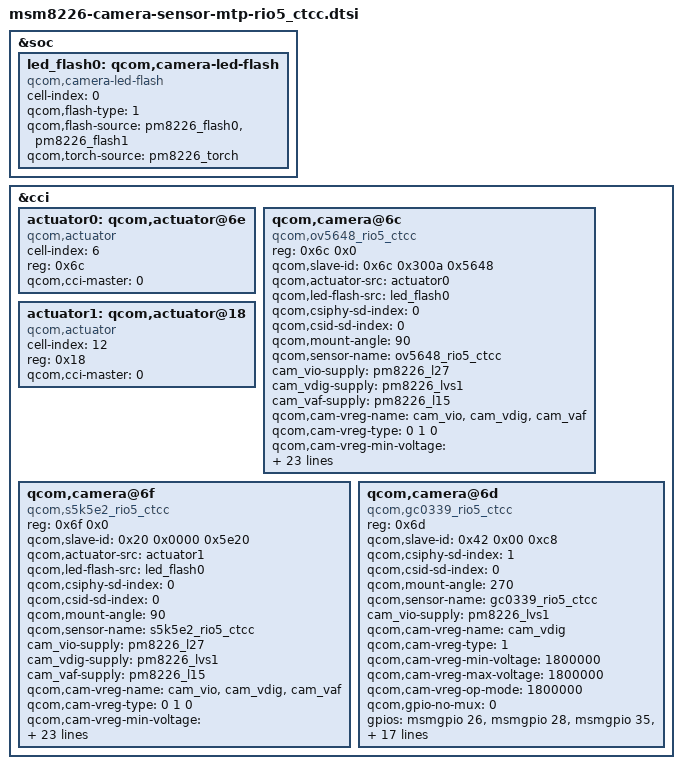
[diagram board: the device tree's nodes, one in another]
/*
 * Copyright (c) 2013, The Linux Foundation. All rights reserved.
 *
 * This program is free software; you can redistribute it and/or modify
 * it under the terms of the GNU General Public License version 2 and
 * only version 2 as published by the Free Software Foundation.
 *
 * This program is distributed in the hope that it will be useful,
 * but WITHOUT ANY WARRANTY; without even the implied warranty of
 * MERCHANTABILITY or FITNESS FOR A PARTICULAR PURPOSE.  See the
 * GNU General Public License for more details.
 *         Modify History For This Module
 * When           Who             What,Where,Why
 * --------------------------------------------------------------------------------------
 * 13/08/22      Hu Jin       Add driver for RoilTF's 1st main CAM
 * 13/08/31      Hu Jin       Add driver for RoilTF's 1st sub CAM
 * 13/12/03      Hu Jin       for rio4g's tuning process(porting from rio4g)
 * 13/12/09      Hu Jin       same with miata ov5648AF
 * 13/12/10      Wang Penglei       Add driver for RIO5 CTCC's 1st sub CAM GC0339
 * 13/12/14      Hu Jin		  same with miata-2
 * 14/01/02      Hu Jin       diff with miata 5M(mount reverse 90°)
 * 14/01/04      Hu Jin       Pictures taken are upside down
 * 14/01/19      Hu Jin       Camera can not be found on production
 * 14/01/21      Hu Jin	  Sub CAM timing
 * 14/02/14      Hu Jin			2nd camera
 * --------------------------------------------------------------------------------------
 */

&soc {

	led_flash0: qcom,camera-led-flash {
		cell-index = <0>;
		compatible = "qcom,camera-led-flash";
		qcom,flash-type = <1>;
		qcom,flash-source = <&pm8226_flash0 &pm8226_flash1>;
		qcom,torch-source = <&pm8226_torch>;
	};
};

&cci {

	actuator0: qcom,actuator@6e {
		cell-index = <6>;/* [PLATFORM]-Mod by TCTNB.HJ, 2013/12/14*/
		reg = <0x6c>;
		compatible = "qcom,actuator";
		qcom,cci-master = <0>;
	};

/*
	qcom,camera@6f {
		compatible = "qcom,ov8825";
		reg = <0x6f>;
		qcom,slave-id = <0x6c 0x300a 0x8825>;
		qcom,csiphy-sd-index = <0>;
		qcom,csid-sd-index = <0>;
		qcom,actuator-src = <&actuator0>;
		qcom,led-flash-src = <&led_flash0>;
		qcom,mount-angle = <270>;
		qcom,sensor-name = "ov8825";
		cam_vdig-supply = <&pm8226_l5>;
		cam_vana-supply = <&pm8226_l19>;
		cam_vio-supply = <&pm8226_lvs1>;
		cam_vaf-supply = <&pm8226_l15>;
		qcom,cam-vreg-name = "cam_vdig", "cam_vio", "cam_vana",
							 "cam_vaf";
		qcom,cam-vreg-type = <0 1 0 0>;
		qcom,cam-vreg-min-voltage = <1200000 0 2850000 2800000>;
		qcom,cam-vreg-max-voltage = <1200000 0 2850000 2800000>;
		qcom,cam-vreg-op-mode = <200000 0 80000 100000>;
		qcom,gpio-no-mux = <0>;
		gpios = <&msmgpio 26 0>,
			<&msmgpio 37 0>,
			<&msmgpio 35 0>;
		qcom,gpio-reset = <1>;
		qcom,gpio-standby = <2>;
		qcom,gpio-req-tbl-num = <0 1 2>;
		qcom,gpio-req-tbl-flags = <1 0 0>;
		qcom,gpio-req-tbl-label = "CAMIF_MCLK",
			"CAM_RESET1",
			"CAM_STANDBY";
		qcom,csi-lane-assign = <0x4320>;
		qcom,csi-lane-mask = <0x1f>;
		qcom,sensor-position = <0>;
		qcom,sensor-mode = <1>;
		qcom,cci-master = <0>;
	};
*/
/*
	qcom,camera@6d {
		compatible = "qcom,ov9724";
		reg = <0x6d>;
		qcom,slave-id = <0x20 0x0 0x9724>;
		qcom,csiphy-sd-index = <1>;
		qcom,csid-sd-index = <1>;
		qcom,mount-angle = <270>;
		qcom,sensor-name = "ov9724";
		cam_vdig-supply = <&pm8226_l5>;
		cam_vana-supply = <&pm8226_l19>;
		cam_vio-supply = <&pm8226_lvs1>;
		qcom,cam-vreg-name = "cam_vdig", "cam_vio", "cam_vana";
		qcom,cam-vreg-type = <0 1 0>;
		qcom,cam-vreg-min-voltage = <1200000 0 2850000>;
		qcom,cam-vreg-max-voltage = <1200000 0 2850000>;
		qcom,cam-vreg-op-mode = <200000 0 80000>;
		qcom,gpio-no-mux = <0>;
		gpios = <&msmgpio 26 0>,
				<&msmgpio 28 0>,
				<&msmgpio 36 0>;
		qcom,gpio-reset = <1>;
		qcom,gpio-standby = <2>;
		qcom,gpio-req-tbl-num = <0 1 2>;
		qcom,gpio-req-tbl-flags = <1 0 0>;
		qcom,gpio-req-tbl-label = "CAMIF_MCLK",
				"CAM_RESET",
				"CAM_STANDBY";
		qcom,gpio-set-tbl-num = <1 1>;
		qcom,gpio-set-tbl-flags = <0 2>;
		qcom,gpio-set-tbl-delay = <1000 4000>;
		qcom,csi-lane-assign = <0x4320>;
		qcom,csi-lane-mask = <0x3>;
		qcom,sensor-position = <1>;
		qcom,sensor-mode = <1>;
		qcom,cci-master = <0>;
		status = "ok";
	};
*/
/* [PLATFORM]-Mod-BEGIN by TCTNB.HJ, 2013/08/22, 1st main CAM dev*/
qcom,camera@6c {
    compatible = "qcom,ov5648_rio5_ctcc";
    reg = <0x6c 0x0>;
    qcom,slave-id = <0x6c 0x300a 0x5648>;
    qcom,actuator-src = <&actuator0>;
    qcom,led-flash-src = <&led_flash0>;
    qcom,csiphy-sd-index = <0>;
    qcom,csid-sd-index = <0>;
    qcom,mount-angle = <90>;
    qcom,sensor-name = "ov5648_rio5_ctcc";
    //cam_vio-supply = <&pm8226_lvs1>;
    cam_vio-supply = <&pm8226_l27>;
    cam_vdig-supply = <&pm8226_lvs1>;
    cam_vaf-supply = <&pm8226_l15>;
    qcom,cam-vreg-name = "cam_vio", "cam_vdig", "cam_vaf";
    qcom,cam-vreg-type = <0 1 0>;
    qcom,cam-vreg-min-voltage = <1500000 1800000 2800000>;
    qcom,cam-vreg-max-voltage = <1500000 1800000 2800000>;
    qcom,cam-vreg-op-mode = <1500000 1800000 100000>;
    qcom,gpio-no-mux = <0>;
    gpios = <&msmgpio 26 0>,
            <&msmgpio 37 0>,
            <&msmgpio 36 0>,
            <&msmgpio 31 0>,
            <&msmgpio 23 0>;
    qcom,gpio-reset = <1>;
    qcom,gpio-standby = <2>;
       qcom,gpio-vana = <3>;
       qcom,gpio-af-pwdm = <4>;
    qcom,gpio-req-tbl-num = <0 1 2 3 4>;
    qcom,gpio-req-tbl-flags = <1 0 0 0 0>;
    qcom,gpio-req-tbl-label = "CAMIF_MCLK",
            "CAM_RESET",
            "CAM_STANDBY",
            "CAM_VANA",
            "CAM_AF_PWDM";
    qcom,gpio-set-tbl-flags = <0 2>;
    qcom,gpio-set-tbl-delay = <1000 4000>;
    qcom,csi-lane-assign = <0x4320>;
    qcom,csi-lane-mask = <0x3>;
    qcom,sensor-position = <0>;
    qcom,sensor-mode = <0>;
    qcom,cci-master = <0>;
};
/* [PLATFORM]-Mod-END by TCTNB.HJ, 2013/08/22 */


/* [PLATFORM]-Mod-BEGIN by TCTNB.HJ, 2014/02/14, 2nd main CAM dev*/
actuator1: qcom,actuator@18 {
    cell-index = <12>;/* [PLATFORM]-Mod-BEGIN by TCTNB.HJ, 2013/11/19, 1st main CAM dev*/
    reg = <0x18>;
    compatible = "qcom,actuator";
    qcom,cci-master = <0>;
};
qcom,camera@6f {
    compatible = "qcom,s5k5e2_rio5_ctcc";
    reg = <0x6f 0x0>;
    qcom,slave-id = <0x20 0x0000 0x5e20>;
    qcom,actuator-src = <&actuator1>;
    qcom,led-flash-src = <&led_flash0>;
    qcom,csiphy-sd-index = <0>;
    qcom,csid-sd-index = <0>;
    qcom,mount-angle = <90>;
    qcom,sensor-name = "s5k5e2_rio5_ctcc";
    cam_vio-supply = <&pm8226_l27>;
    cam_vdig-supply = <&pm8226_lvs1>;
    cam_vaf-supply = <&pm8226_l15>;
    qcom,cam-vreg-name =  "cam_vio", "cam_vdig", "cam_vaf";
    qcom,cam-vreg-type = <0 1 0>;
    qcom,cam-vreg-min-voltage = <1200000 1800000 2800000>;
    qcom,cam-vreg-max-voltage = <1200000 1800000 2800000>;
    qcom,cam-vreg-op-mode = <1200000 1800000 100000>;
    qcom,gpio-no-mux = <0>;
    gpios = <&msmgpio 26 0>,
            <&msmgpio 37 0>,
            <&msmgpio 36 0>,
            <&msmgpio 31 0>,
            <&msmgpio 23 0>;
    qcom,gpio-reset = <1>;
    qcom,gpio-standby = <2>;
       qcom,gpio-vana = <3>;
       qcom,gpio-af-pwdm = <4>;
    qcom,gpio-req-tbl-num = <0 1 2 3 4>;
    qcom,gpio-req-tbl-flags = <1 0 0 0 0>;
    qcom,gpio-req-tbl-label = "CAMIF_MCLK",
            "CAM_RESET",
            "CAM_STANDBY",
            "CAM_VANA",
            "CAM_AF_PWDM";
    qcom,gpio-set-tbl-flags = <0 2>;
    qcom,gpio-set-tbl-delay = <1000 4000>;
    qcom,csi-lane-assign = <0x4320>;
    qcom,csi-lane-mask = <0x3>;
    qcom,sensor-position = <0>;
    qcom,sensor-mode = <0>;
    qcom,cci-master = <0>;
};
/* [PLATFORM]-Mod-END by TCTNB.HJ, 2013/08/22 */

/* [PLATFORM]-Mod-BEGIN by TCTNB.HJ, 2013/08/31, 1st sub CAM dev*/
	qcom,camera@6d {
	compatible = "qcom,gc0313";
	reg = <0x6d>;
	qcom,slave-id = <0x42 0xf0 0xd000>;
	qcom,csiphy-sd-index = <1>;
	qcom,csid-sd-index = <0>;
	qcom,mount-angle = <270>;
	qcom,sensor-name = "gc0313";
	cam_vio-supply = <&pm8226_lvs1>;
	qcom,cam-vreg-name = "cam_vio";
	qcom,cam-vreg-type = <1>;
	qcom,cam-vreg-min-voltage = <0>;
	qcom,cam-vreg-max-voltage = <0>;
	qcom,cam-vreg-op-mode = <0>;
	qcom,gpio-no-mux = <0>;
	gpios = <&msmgpio 26 0>,
			<&msmgpio 28 0>,
			<&msmgpio 35 0>;
	qcom,gpio-reset = <1>;
	qcom,gpio-standby = <2>;
	qcom,gpio-req-tbl-num = <0 1 2>;
	qcom,gpio-req-tbl-flags = <1 0 0>;
	qcom,gpio-req-tbl-label = "CAMIF_MCLK",
			"CAM_RESET",
			"CAM_STANDBY";
	qcom,gpio-set-tbl-num = <1 1>;
	qcom,gpio-set-tbl-flags = <0 2>;
	qcom,gpio-set-tbl-delay = <1000 4000>;
	qcom,csi-lane-assign = <0x4320>;
	qcom,csi-lane-mask = <0x3>;
	qcom,sensor-position = <1>;
	qcom,sensor-mode = <1>;
	qcom,cci-master = <0>;
    status = "ok";
	};
/* [PLATFORM]-Mod-END by TCTNB.HJ, 2013/08/31 */

/* [PLATFORM]-Add-BEGIN by TCTNB.WPL, 2013/12/10, RIO5 CTCC 1st sub CAM dev, refer to bug564642 */
	qcom,camera@6d {
	compatible = "qcom,gc0339_rio5_ctcc";
	reg = <0x6d>;
	qcom,slave-id = <0x42 0x00 0xc8>;
	qcom,csiphy-sd-index = <1>;
	qcom,csid-sd-index = <0>;
	qcom,mount-angle = <270>;
	qcom,sensor-name = "gc0339_rio5_ctcc";
	cam_vdig-supply = <&pm8226_lvs1>;
	qcom,cam-vreg-name = "cam_vdig";
	qcom,cam-vreg-type = <1>;
	qcom,cam-vreg-min-voltage = <1800000>;
	qcom,cam-vreg-max-voltage = <1800000>;
	qcom,cam-vreg-op-mode = <1800000>;
	qcom,gpio-no-mux = <0>;
	gpios = <&msmgpio 26 0>,
			<&msmgpio 28 0>,
			<&msmgpio 35 0>,
			<&msmgpio 31 0>;
	qcom,gpio-reset = <1>;
	qcom,gpio-standby = <2>;
       qcom,gpio-vana = <3>;
	qcom,gpio-req-tbl-num = <0 1 2 3>;
	qcom,gpio-req-tbl-flags = <1 0 0 0>;
	qcom,gpio-req-tbl-label = "CAMIF_MCLK",
			"CAM_RESET",
			"CAM_STANDBY",
			"CAM_VANA";
	qcom,gpio-set-tbl-num = <1 1>;
	qcom,gpio-set-tbl-flags = <0 2>;
	qcom,gpio-set-tbl-delay = <1000 4000>;
	qcom,csi-lane-assign = <0x4320>;
	qcom,csi-lane-mask = <0x3>;
	qcom,sensor-position = <1>;
	qcom,sensor-mode = <0>;
	qcom,cci-master = <0>;
	status = "ok";
	};
/* [PLATFORM]-Add-END by TCTNB.WPL, 2013/12/10 */
};
